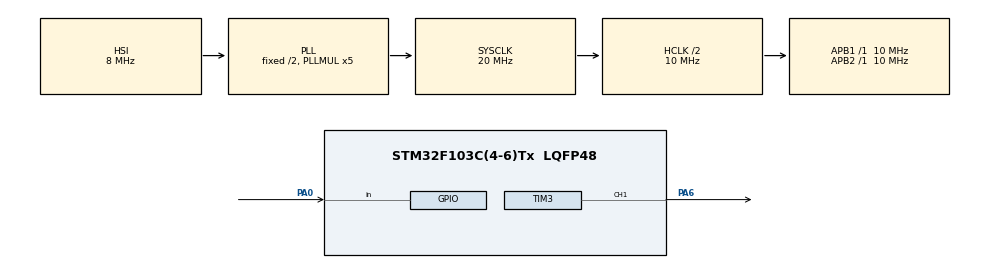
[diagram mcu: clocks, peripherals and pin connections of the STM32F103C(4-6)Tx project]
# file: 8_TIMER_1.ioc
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Mcu.Family=STM32F1
Mcu.Name=STM32F103C(4-6)Tx
Mcu.Package=LQFP48
NVIC.PriorityGroup=NVIC_PRIORITYGROUP_4
PA0-WKUP.GPIO_PuPd=GPIO_PULLDOWN
PA0-WKUP.Signal=GPIO_Input
PA6.Signal=S_TIM3_CH1
ProjectManager.HeapSize=0x200
ProjectManager.StackSize=0x400
ProjectManager.TargetToolchain=STM32CubeIDE
RCC.AHBCLKDivider=RCC_SYSCLK_DIV2
RCC.AHBFreq_Value=10000000
RCC.APB1Freq_Value=10000000
RCC.APB1TimFreq_Value=10000000
RCC.APB2Freq_Value=10000000
RCC.APB2TimFreq_Value=10000000
RCC.HCLKFreq_Value=10000000
RCC.PLLMUL=RCC_PLL_MUL5
RCC.SYSCLKFreq_VALUE=20000000
RCC.SYSCLKSource=RCC_SYSCLKSOURCE_PLLCLK
RCC.USBFreq_Value=20000000
SH.S_TIM3_CH1.0=TIM3_CH1,Output Compare1 CH1
TIM3.Channel-Output\ Compare1\ CH1=TIM_CHANNEL_1
TIM3.OCMode_1=TIM_OCMODE_TOGGLE
VP_TIM3_VS_ClockSourceINT.Mode=Internal
board=custom

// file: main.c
/* USER CODE BEGIN Header */
/**
  ******************************************************************************
  * @file           : main.c
  * @brief          : Main program body
  ******************************************************************************
  * @attention
  *
  * Copyright (c) 2023 STMicroelectronics.
  * All rights reserved.
  *
  * This software is licensed under terms that can be found in the LICENSE file
  * in the root directory of this software component.
  * If no LICENSE file comes with this software, it is provided AS-IS.
  *
  ******************************************************************************
  */
/* USER CODE END Header */
#include "main.h"

TIM_HandleTypeDef htim3;

/* USER CODE BEGIN PV */
uint16_t freq_lut[10]={500,250,167,125,100,83,71,62,55,50};
uint8_t up_down_flag=1;
uint8_t counter=0;
/* USER CODE END PV */

void SystemClock_Config(void);
static void MX_GPIO_Init(void);
static void MX_TIM3_Init(void);

int main(void)
{

  /* MCU Configuration--------------------------------------------------------*/

  /* Reset of all peripherals, Initializes the Flash interface and the Systick. */
  HAL_Init();

  /* Configure the system clock */
  SystemClock_Config();

  /* Initialize all configured peripherals */
  MX_GPIO_Init();
  MX_TIM3_Init();

  /* Infinite loop */
  while (1)
  {

    /* USER CODE BEGIN 3 */
	  if(HAL_GPIO_ReadPin(GPIOA, GPIO_PIN_0)){
		  HAL_Delay(20);
		  HAL_TIM_OC_Stop(&htim3, TIM_CHANNEL_1);
		  if(counter>=9){
			  up_down_flag=0;
		  }
		  else if(counter<=0){
			  up_down_flag=1;
		  }
		  counter=up_down_flag ? (counter+1) : (counter-1);
		  __HAL_TIM_SET_AUTORELOAD(&htim3,freq_lut[counter]-1);
		  HAL_TIM_OC_Start(&htim3,TIM_CHANNEL_1);
	  }
  }
  /* USER CODE END 3 */
}

void SystemClock_Config(void)
{
  RCC_OscInitTypeDef RCC_OscInitStruct = {0};
  RCC_ClkInitTypeDef RCC_ClkInitStruct = {0};

  /** Initializes the RCC Oscillators according to the specified parameters
  * in the RCC_OscInitTypeDef structure.
  */
  RCC_OscInitStruct.OscillatorType = RCC_OSCILLATORTYPE_HSI;
  RCC_OscInitStruct.HSIState = RCC_HSI_ON;
  RCC_OscInitStruct.HSICalibrationValue = RCC_HSICALIBRATION_DEFAULT;
  RCC_OscInitStruct.PLL.PLLState = RCC_PLL_ON;
  RCC_OscInitStruct.PLL.PLLSource = RCC_PLLSOURCE_HSI_DIV2;
  RCC_OscInitStruct.PLL.PLLMUL = RCC_PLL_MUL5;
  if (HAL_RCC_OscConfig(&RCC_OscInitStruct) != HAL_OK)
  {
    Error_Handler();
  }

  /** Initializes the CPU, AHB and APB buses clocks
  */
  RCC_ClkInitStruct.ClockType = RCC_CLOCKTYPE_HCLK|RCC_CLOCKTYPE_SYSCLK
                              |RCC_CLOCKTYPE_PCLK1|RCC_CLOCKTYPE_PCLK2;
  RCC_ClkInitStruct.SYSCLKSource = RCC_SYSCLKSOURCE_PLLCLK;
  RCC_ClkInitStruct.AHBCLKDivider = RCC_SYSCLK_DIV2;
  RCC_ClkInitStruct.APB1CLKDivider = RCC_HCLK_DIV1;
  RCC_ClkInitStruct.APB2CLKDivider = RCC_HCLK_DIV1;

  if (HAL_RCC_ClockConfig(&RCC_ClkInitStruct, FLASH_LATENCY_0) != HAL_OK)
  {
    Error_Handler();
  }
}

static void MX_TIM3_Init(void)
{

  TIM_ClockConfigTypeDef sClockSourceConfig = {0};
  TIM_MasterConfigTypeDef sMasterConfig = {0};
  TIM_OC_InitTypeDef sConfigOC = {0};

  htim3.Instance = TIM3;
  htim3.Init.Prescaler = 0;
  htim3.Init.CounterMode = TIM_COUNTERMODE_UP;
  htim3.Init.Period = 65535;
  htim3.Init.ClockDivision = TIM_CLOCKDIVISION_DIV1;
  htim3.Init.AutoReloadPreload = TIM_AUTORELOAD_PRELOAD_DISABLE;
  if (HAL_TIM_Base_Init(&htim3) != HAL_OK)
  {
    Error_Handler();
  }
  sClockSourceConfig.ClockSource = TIM_CLOCKSOURCE_INTERNAL;
  if (HAL_TIM_ConfigClockSource(&htim3, &sClockSourceConfig) != HAL_OK)
  {
    Error_Handler();
  }
  if (HAL_TIM_OC_Init(&htim3) != HAL_OK)
  {
    Error_Handler();
  }
  sMasterConfig.MasterOutputTrigger = TIM_TRGO_RESET;
  sMasterConfig.MasterSlaveMode = TIM_MASTERSLAVEMODE_DISABLE;
  if (HAL_TIMEx_MasterConfigSynchronization(&htim3, &sMasterConfig) != HAL_OK)
  {
    Error_Handler();
  }
  sConfigOC.OCMode = TIM_OCMODE_TOGGLE;
  sConfigOC.Pulse = 0;
  sConfigOC.OCPolarity = TIM_OCPOLARITY_HIGH;
  sConfigOC.OCFastMode = TIM_OCFAST_DISABLE;
  if (HAL_TIM_OC_ConfigChannel(&htim3, &sConfigOC, TIM_CHANNEL_1) != HAL_OK)
  {
    Error_Handler();
  }
  HAL_TIM_MspPostInit(&htim3);

}

static void MX_GPIO_Init(void)
{
  GPIO_InitTypeDef GPIO_InitStruct = {0};

  /* GPIO Ports Clock Enable */
  __HAL_RCC_GPIOA_CLK_ENABLE();

  /*Configure GPIO pin : PA0 */
  GPIO_InitStruct.Pin = GPIO_PIN_0;
  GPIO_InitStruct.Mode = GPIO_MODE_INPUT;
  GPIO_InitStruct.Pull = GPIO_PULLDOWN;
  HAL_GPIO_Init(GPIOA, &GPIO_InitStruct);

}

void Error_Handler(void)
{
  __disable_irq();
  while (1)
  {
  }
}
